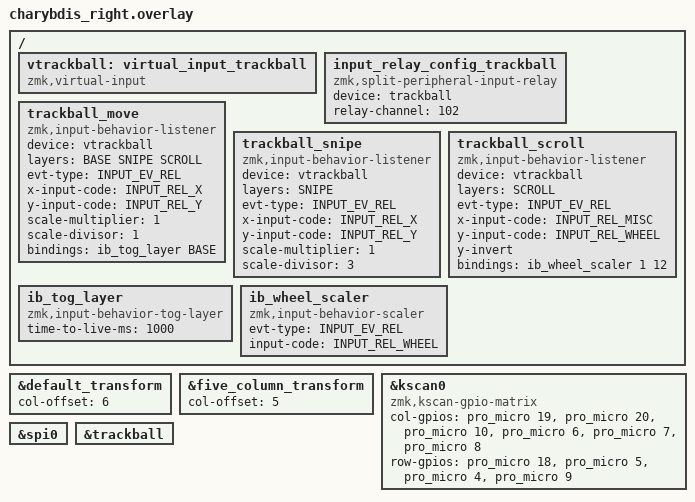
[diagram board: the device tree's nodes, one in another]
#include "charybdis.dtsi"
#include "charybdis_3610.dtsi"
#include <behaviors/mouse_keys.dtsi>

&default_transform {
	col-offset = <6>;
};

&five_column_transform {
	col-offset = <5>;
};

&kscan0 {
	compatible = "zmk,kscan-gpio-matrix";
	
	col-gpios
		= <&pro_micro 19 (GPIO_ACTIVE_HIGH | GPIO_PULL_DOWN)>
		, <&pro_micro 20 (GPIO_ACTIVE_HIGH | GPIO_PULL_DOWN)>
		, <&pro_micro 10 (GPIO_ACTIVE_HIGH | GPIO_PULL_DOWN)>
		, <&pro_micro 6 (GPIO_ACTIVE_HIGH | GPIO_PULL_DOWN)>
		, <&pro_micro 7 (GPIO_ACTIVE_HIGH | GPIO_PULL_DOWN)>
		, <&pro_micro 8 (GPIO_ACTIVE_HIGH | GPIO_PULL_DOWN)>
		;

	row-gpios
		= <&pro_micro 18 GPIO_ACTIVE_HIGH>
		, <&pro_micro 5 GPIO_ACTIVE_HIGH>
		, <&pro_micro 4 GPIO_ACTIVE_HIGH>
		, <&pro_micro 9 GPIO_ACTIVE_HIGH>
		;
};

&spi0 {
    status = "okay";
};

&trackball {
    status = "okay";
};

/ {
	vtrackball: virtual_input_trackball {
		compatible = "zmk,virtual-input";
	};

	input_relay_config_trackball {
		compatible = "zmk,split-peripheral-input-relay";
		device = <&trackball>;
		relay-channel = <102>;
	};

  trackball_move: trackball_move {
      compatible = "zmk,input-behavior-listener";
      device = <&vtrackball>;
      layers = <BASE SNIPE SCROLL>;
      evt-type = <INPUT_EV_REL>;
      x-input-code = <INPUT_REL_X>;
      y-input-code = <INPUT_REL_Y>;
      scale-multiplier = <1>;
      scale-divisor = <1>;
      bindings = <&ib_tog_layer BASE>;
  };

  trackball_snipe: trackball_snipe {
      compatible = "zmk,input-behavior-listener";
      device = <&vtrackball>;
      layers = <SNIPE>;
      evt-type = <INPUT_EV_REL>;
      x-input-code = <INPUT_REL_X>;
      y-input-code = <INPUT_REL_Y>;
      scale-multiplier = <1>;
      scale-divisor = <3>;
  };

  trackball_scroll: trackball_scroll {
      compatible = "zmk,input-behavior-listener";
      device = <&vtrackball>;
      layers = <SCROLL>;
      evt-type = <INPUT_EV_REL>;
      x-input-code = <INPUT_REL_MISC>;
      y-input-code = <INPUT_REL_WHEEL>;
      y-invert;
      bindings = <&ib_wheel_scaler 1 12>;
  };

  ib_tog_layer: ib_tog_layer {
      compatible = "zmk,input-behavior-tog-layer";
      #binding-cells = <1>;
      time-to-live-ms = <1000>;
  };

  // Smooth scroll accumulator
  ib_wheel_scaler: ib_wheel_scaler {
      compatible = "zmk,input-behavior-scaler";
      #binding-cells = <2>;
      evt-type = <INPUT_EV_REL>;
      input-code = <INPUT_REL_WHEEL>;
  };
};

